# SPC1169 register map
File version: 2022071043481212
CPU: cm4 r1p0, little endian, no MPU, FPU, 4 interrupt priority bits
Registers are 32-bit, read-write, reset 0x0 unless marked. A register's access mark holds for its fields unless they carry their own. Offsets are from the block's base; [hi:lo] are bit positions; 'fields as' and 'values as' point back to an identical list.

## ENGR
Base 0x40000F00
0x14 ADC1OFFSET — FuSa ADC Offset Trim Register
  [31:0] VAL — Offset trim, which is a signed number within [-4096, 4095]
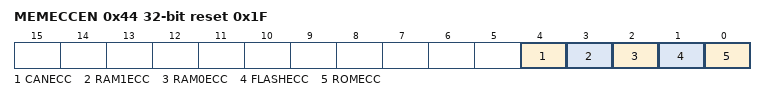
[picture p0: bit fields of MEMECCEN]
0x44 MEMECCEN reset 0x1F — Memory ECC Enable Register
  [all] fields
    0=DISABLE; 1=ENABLE
  [4] CANECC — CAN ECC enable
  [3] RAM1ECC — RAM1 ECC enable
  [2] RAM0ECC — RAM0 ECC enable
  [1] FLASHECC — FLASH ECC enable
  [0] ROMECC — ROM ECC enable

## WDT0
Base 0x40001000
Same registers: WDT1 0x40001100
0x00 WDTLOAD reset 0x3D09000 — Watchdog Timer Load Register
  [31:0] VAL — Load value (Minimum valid value is 1). The value from which the counter is to decrease. When this register is written to, the count is immediately restarted from the new value.
0x04 WDTCNT ro reset 0x3D09000 — Watchdog Timer Current Value Register
  [31:0] VAL — Current value of the decrementing counter.
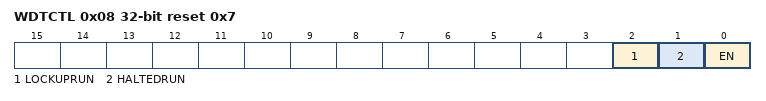
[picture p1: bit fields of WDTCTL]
0x08 WDTCTL reset 0x7 — Watchdog Timer Control Register
  [2] LOCKUPRUN — Allow watchdog to run during CPU lockup mode
    0=DISABLE (Disable the counter and reset it to WDTLOAD when CPU is in lockup mode); 1=ENABLE (Enable the counter when CPU is in lockup mode)
  [1] HALTEDRUN — Allow watchdog to run during CPU halted mode
    0=DISABLE (Disable the counter and reset it to WDTLOAD when CPU is in halted mode); 1=ENABLE (Enable the counter when CPU is in halted mode)
  [0] EN — Enable the watchdog counter
    0=DISABLE (Disable the counter and reset it to WDTLOAD); 1=ENABLE (Enable the counter)
0x0C WDTRAWIF ro — Watchdog Timer Raw Interrupt Flag Register
  [0] INT — Raw interrupt flag from the counter. The value is ANDed with WDTIE to create the masked interrupt, which is passed to the interrupt output pin.
    0=NOT_OCCUR (Raw interrupt does not occur); 1=OCCUR (Raw interrupt occurred)
0x10 WDTIF ro — Watchdog Timer Interrupt Flag Register
  [0] INT — Interrupt flag from the counter. The value is the logical AND of WDTRAWIF and WDTIE
    0=NOT_OCCUR (Masked interrupt does not occur); 1=OCCUR (Masked interrupt occurred)
0x14 WDTIC — Watchdog Timer Interrupt Clear Register
  [0] INT — Clear interrupt. If write 1 to this bit when WDTCNT is within [WDTTHL, WDTTHH], the WDTCNT will be reset to WDTLOAD
    0=NO_EFFECT (Write a 0 has no effect and always read back 0.); 1=CLEAR (Write a 1 clears both the WDTRAWIF and WDTIF, and reset counter to WDTLOAD when WDTCNT is within [WDTTHL, WDTTHH]. This bit is self-cleared to 0.)
0x18 WDTIE reset 0x1 — Watchdog Timer Interrupt Enable Register
  [0] INT — Interrupt enable
    0=DISABLE; 1=ENABLE
0x1C WDTTHL — Watchdog Windowed-Feed Low Threshold Register
  [31:0] VAL — Watchdog can be feed (via write a 1 to WDTIC) only when WDTCNT is within [WDTTHL, WDTTHH]
0x20 WDTTHH reset 0xFFFFFFFF — Watchdog Windowed-Feed Low Threshold Register
  fields as WDTTHL
0x24 WDTREGKEY — Watchdog Register Write-Allow Key Register
  [31:0] KEY — Write 0x1ACCE551 to unlock protected watchdog registers

## TIMER0
Base 0x40001800
Same registers: TIMER1 0x40001900, TIMER2 0x40001A00
0x00 TMRLOAD — Timer Load Register
  [31:0] VAL — Load value from which the counter is to decrease. A write to this register sets the current counter value.
0x04 TMRCNT — Timer Counter Value Register
  [31:0] VAL — Current value of timer counter. A write to this register sets the current counter value.
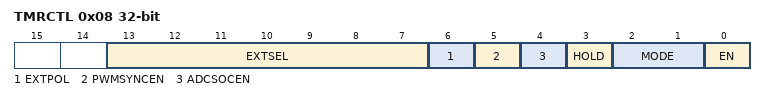
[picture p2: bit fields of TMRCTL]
0x08 TMRCTL — Timer Control Register
  [13:7] EXTSEL — External input source select (GPIO number)
  [6] EXTPOL — External input polarity
    0=ACTIVE_LOW (Active low. Enable counter when input is low for gated timer mode. Trigger event upon falling edge of input for eevnt counter and event capture modes); 1=ACTIVE_HIGH (Active high. Enable counter when input is high for gated timer mode. Trigger event upon rising edge of input for eevnt counter and event capture modes)
  [5] PWMSYNCEN — PWMSYNC generation enable
    0=DISABLE (Do not generate PWMSYNC); 1=ENABLE (Generate PWMSYNC whenever TMRCNT counts down to 0)
  [4] ADCSOCEN — ADCSOC generation enable
    0=DISABLE (Do not generate ADCSOC); 1=ENABLE (Generate ADCSOC whenever TMRCNT counts down to 0)
  [3] HOLD — Hold counter value upon falling edge of TMRCTL.EN
    0=DISABLE (Reset counter to 0 upon falling edge of TMRCTL.EN); 1=ENABLE (Hold counter value upon falling edge of TMRCTL.EN)
  [2:1] MODE — Operation mode
    0=GENERAL_TIMER (General timer (down count)); 1=GATED_TIMER (Down counter timer enabled by external input); 2=EVENT_COUNTER (Down counter for external input event); 3=EVENT_CAPTURE (Capture counter value upon external input event)
  [0] EN — Timer enable
    0=DISABLE (Disable Timer); 1=ENABLE (Enable Timer)
0x0C TMRRAWIF ro — Timer Raw Interrupt Flag Register
  [0] INT — Raw timer interrupt flag. This bit is set whenever TMRCNT counts down to 0 and cleared only by writing a 1 to TMRIC
    0=NOT_OCCUR (Raw interrupt does not occurre); 1=OCCUR (Raw interrupt occurred)
0x10 TMRIF ro — Timer Interrupt Flag Register
  [0] INT — Masked timer interrupt flag. This bit is the logic AND of TMRRAWIF and TMRIE
    0=NOT_OCCUR (Masked interrupt does not occur); 1=OCCUR (Masked interrupt occurred and issued to CPU. No further interrupt will be issued until the flag is cleared)
0x14 TMRIC — Timer Interrupt Clear Register
  [0] INT — Timer interrupt clear
    0=NO_EFFECT (Write a 0 has no effect and always reads back 0.); 1=CLEAR (Writing a 1 clears the TMRRAWIF and TMRIF flag. This bit is self-cleared to 0.)
0x18 TMRIE — Timer Interrupt Enable Register
  [0] INT — Timer interrupt enable. This bit does not affect TMRRAWIF and PWMSYNC/ADCSOC generation
    0=DISABLE (Do not issue interrupt to CPU); 1=ENABLE (Issue interrupt to CPU whenever TMRCNT counts down to 0)
0x1C TMRREGKEY reset 0x1ACCE551 — Timer Register Write-Allow Key Register
  [31:0] KEY — Write 0x1ACCE551 to unlock protected timer registers
